# CY8C5888LTI_LP097 register map
File version: 0.1
Registers are 8-bit, read-write, no defined reset value unless marked. A register's access mark holds for its fields unless they carry their own. Offsets are from the block's base; [hi:lo] are bit positions; {n}, {i} and the like mark numbered series; 'fields as' and 'values as' point back to an identical list.

## Timer_Sonar
Base 0x00000000
0x40006504 Timer_Sonar_COUNTER 24-bit — UDB.A0 - Current Down Counter Value
0x40006524 Timer_Sonar_PERIOD 24-bit — UDB.D0 - Assigned Period
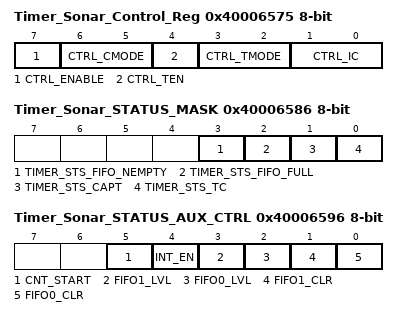
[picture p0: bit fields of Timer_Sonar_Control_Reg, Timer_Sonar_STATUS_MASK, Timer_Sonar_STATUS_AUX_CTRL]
0x40006575 Timer_Sonar_Control_Reg — UDB Control Register - Assigned Control Register Value
  [7] CTRL_ENABLE — Enable the Timer
  [6:5] CTRL_CMODE — Capture Mode
  [4] CTRL_TEN — Trigger Enable Bit
  [3:2] CTRL_TMODE — Trigger Mode
  [1:0] CTRL_IC — Interrupt Count
0x40006586 Timer_Sonar_STATUS_MASK — UDB Status bits Interrupt Mask Enable Register
  [3] TIMER_STS_FIFO_NEMPTY ro — FIFO Empty status
  [2] TIMER_STS_FIFO_FULL ro — FIFO Full Status
  [1] TIMER_STS_CAPT ro — Enables the Interrupt on Capture
  [0] TIMER_STS_TC ro — Enables the Interrupt on TC
0x40006596 Timer_Sonar_STATUS_AUX_CTRL — UDB Auxilliary Control Register
  [5] CNT_START — FIFO0 clear
    0=E_CNT_START0 (Disable counter); 1=E_CNT_START1 (Enable counter)
  [4] INT_EN
    0=E_INT_EN0 (Interrupt disabled); 1=E_INT_EN1 (Interrupt enabled)
  [3] FIFO1_LVL — FIFO level
    0=E_FIFO_LVL_0 (FIFO LVL: input mode: FIFO not full; output mode: FIFO not empty); 1=E_FIFO_LVL_1 (FIFO LVL: input mode: FIFO at least 1/2 empty; output mode: FIFO at least 1/2 full)
  [2] FIFO0_LVL — FIFO level
    values as FIFO1_LVL
  [1] FIFO1_CLR — FIFO1 clear
    0=E_FIFO_CLR_0 (Normal FIFO operation); 1=E_FIFO_CLR_1 (Clear FIFO state)
  [0] FIFO0_CLR — FIFO0 clear
    values as FIFO1_CLR

## Delay_Timer
Base 0x00000000
0x4000640C Delay_Timer_COUNTER 16-bit — UDB.A0 - Current Down Counter Value
0x4000642C Delay_Timer_PERIOD 16-bit — UDB.D0 - Assigned Period
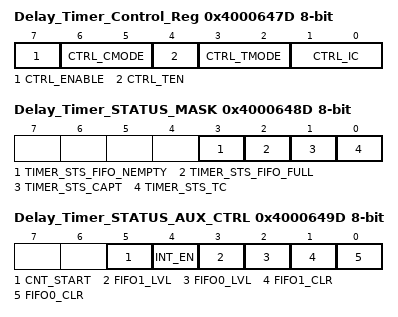
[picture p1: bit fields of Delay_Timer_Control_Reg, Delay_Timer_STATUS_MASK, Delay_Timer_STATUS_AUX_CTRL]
0x4000647D Delay_Timer_Control_Reg — UDB Control Register - Assigned Control Register Value
  [7] CTRL_ENABLE — Enable the Timer
  [6:5] CTRL_CMODE — Capture Mode
  [4] CTRL_TEN — Trigger Enable Bit
  [3:2] CTRL_TMODE — Trigger Mode
  [1:0] CTRL_IC — Interrupt Count
0x4000648D Delay_Timer_STATUS_MASK — UDB Status bits Interrupt Mask Enable Register
  [3] TIMER_STS_FIFO_NEMPTY ro — FIFO Empty status
  [2] TIMER_STS_FIFO_FULL ro — FIFO Full Status
  [1] TIMER_STS_CAPT ro — Enables the Interrupt on Capture
  [0] TIMER_STS_TC ro — Enables the Interrupt on TC
0x4000649D Delay_Timer_STATUS_AUX_CTRL — UDB Auxilliary Control Register
  [5] CNT_START — FIFO0 clear
    0=E_CNT_START0 (Disable counter); 1=E_CNT_START1 (Enable counter)
  [4] INT_EN
    0=E_INT_EN0 (Interrupt disabled); 1=E_INT_EN1 (Interrupt enabled)
  [3] FIFO1_LVL — FIFO level
    0=E_FIFO_LVL_0 (FIFO LVL: input mode: FIFO not full; output mode: FIFO not empty); 1=E_FIFO_LVL_1 (FIFO LVL: input mode: FIFO at least 1/2 empty; output mode: FIFO at least 1/2 full)
  [2] FIFO0_LVL — FIFO level
    values as FIFO1_LVL
  [1] FIFO1_CLR — FIFO1 clear
    0=E_FIFO_CLR_0 (Normal FIFO operation); 1=E_FIFO_CLR_1 (Clear FIFO state)
  [0] FIFO0_CLR — FIFO0 clear
    values as FIFO1_CLR

## UART_1 — UART
Base 0x00000000
0x40006441 TX_UART_1_TX_DATA — TX Data Register
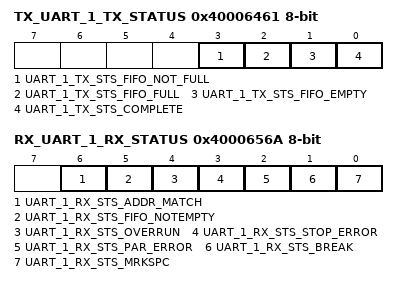
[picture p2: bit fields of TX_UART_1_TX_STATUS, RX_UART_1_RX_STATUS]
0x40006461 TX_UART_1_TX_STATUS — TX status register
  [3] UART_1_TX_STS_FIFO_NOT_FULL ro, [2] UART_1_TX_STS_FIFO_FULL ro, [1] UART_1_TX_STS_FIFO_EMPTY ro, [0] UART_1_TX_STS_COMPLETE ro
0x4000652A RX_UART_1_RX_ADDRESS1 — RX Address1 Register
0x4000653A RX_UART_1_RX_ADDRESS2 — RX Address2 Register
0x4000654A RX_UART_1_RX_DATA — RX Data Register
0x4000656A RX_UART_1_RX_STATUS — RX status register
  [6] UART_1_RX_STS_ADDR_MATCH ro, [5] UART_1_RX_STS_FIFO_NOTEMPTY ro, [4] UART_1_RX_STS_OVERRUN ro, [3] UART_1_RX_STS_STOP_ERROR ro, [2] UART_1_RX_STS_PAR_ERROR ro, [1] UART_1_RX_STS_BREAK ro, [0] UART_1_RX_STS_MRKSPC ro

## Timer_StepperX
Base 0x00000000
0x40006508 Timer_StepperX_COUNTER 16-bit — UDB.A0 - Current Down Counter Value
0x40006528 Timer_StepperX_PERIOD 16-bit — UDB.D0 - Assigned Period
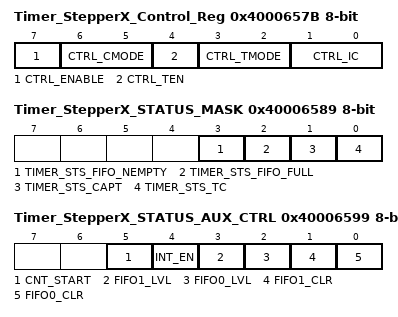
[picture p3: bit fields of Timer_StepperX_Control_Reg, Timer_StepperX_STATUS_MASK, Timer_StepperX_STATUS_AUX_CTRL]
0x4000657B Timer_StepperX_Control_Reg — UDB Control Register - Assigned Control Register Value
  [7] CTRL_ENABLE — Enable the Timer
  [6:5] CTRL_CMODE — Capture Mode
  [4] CTRL_TEN — Trigger Enable Bit
  [3:2] CTRL_TMODE — Trigger Mode
  [1:0] CTRL_IC — Interrupt Count
0x40006589 Timer_StepperX_STATUS_MASK — UDB Status bits Interrupt Mask Enable Register
  [3] TIMER_STS_FIFO_NEMPTY ro — FIFO Empty status
  [2] TIMER_STS_FIFO_FULL ro — FIFO Full Status
  [1] TIMER_STS_CAPT ro — Enables the Interrupt on Capture
  [0] TIMER_STS_TC ro — Enables the Interrupt on TC
0x40006599 Timer_StepperX_STATUS_AUX_CTRL — UDB Auxilliary Control Register
  [5] CNT_START — FIFO0 clear
    0=E_CNT_START0 (Disable counter); 1=E_CNT_START1 (Enable counter)
  [4] INT_EN
    0=E_INT_EN0 (Interrupt disabled); 1=E_INT_EN1 (Interrupt enabled)
  [3] FIFO1_LVL — FIFO level
    0=E_FIFO_LVL_0 (FIFO LVL: input mode: FIFO not full; output mode: FIFO not empty); 1=E_FIFO_LVL_1 (FIFO LVL: input mode: FIFO at least 1/2 empty; output mode: FIFO at least 1/2 full)
  [2] FIFO0_LVL — FIFO level
    values as FIFO1_LVL
  [1] FIFO1_CLR — FIFO1 clear
    0=E_FIFO_CLR_0 (Normal FIFO operation); 1=E_FIFO_CLR_1 (Clear FIFO state)
  [0] FIFO0_CLR — FIFO0 clear
    values as FIFO1_CLR

## ADC_Moisture — SAR ADC
Base 0x00000000
0x40004616 SAR_TR0 — SAR trim register
{0x40005908+i} SAR_CSR{i} (i=0..6) — SAR status and control register {i}
0x40005B28 SAR_SW0 — SAR Analog Routing Register 0
{0x40005B28+i} SAR_SW{i} (i=2..4) — SAR Analog Routing Register {i}
0x40005B2E SAR_SW6 — SAR Analog Routing Register 6
0x40005B2F SAR_CLK — SAR Clock Selection Register
0x40005BA2 SAR_WRK 16-bit — SAR working register
